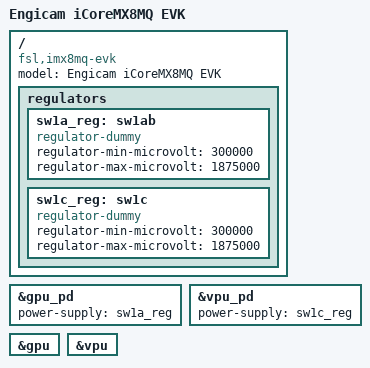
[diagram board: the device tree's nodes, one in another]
/*
 * Copyright 2017 NXP
 * Copyright 2018 Engicam srl.
 *
 * This program is free software; you can redistribute it and/or
 * modify it under the terms of the GNU General Public License
 * as published by the Free Software Foundation; either version 2
 * of the License, or (at your option) any later version.
 *
 * This program is distributed in the hope that it will be useful,
 * but WITHOUT ANY WARRANTY; without even the implied warranty of
 * MERCHANTABILITY or FITNESS FOR A PARTICULAR PURPOSE.  See the
 * GNU General Public License for more details.
 */


#include "../freescale/fsl-imx8mq.dtsi"

/ {
      model = "Engicam iCoreMX8MQ EVK";
	  compatible = "fsl,imx8mq-evk", "fsl,imx8mq";
    
    regulators {       
            sw1a_reg: sw1ab {
       			compatible = "regulator-dummy"; 
                regulator-min-microvolt = <300000>;
                regulator-max-microvolt = <1875000>;
                };

            sw1c_reg: sw1c {
                compatible = "regulator-dummy"; 
                regulator-min-microvolt = <300000>;
                regulator-max-microvolt = <1875000>;
            };
    };

};
            
&gpu_pd {
	power-supply = <&sw1a_reg>;
};

&vpu_pd {
	power-supply = <&sw1c_reg>;
};

&gpu {
	status = "okay";
};

&vpu {
	status = "okay";
};
